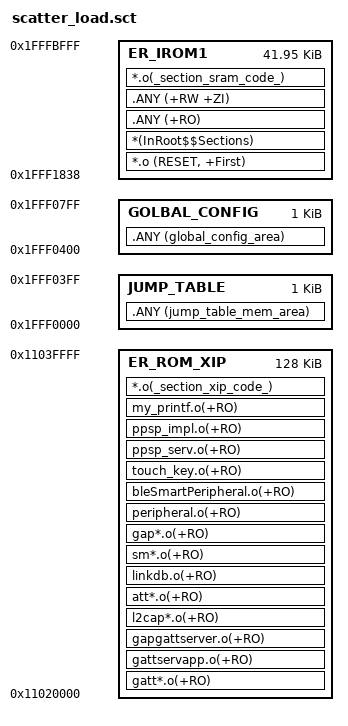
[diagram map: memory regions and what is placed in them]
; *************************************************************
; *** Scatter-Loading Description File generated by uVision ***
; *************************************************************


LR_IROM1 0x1fff1838 0x0A7C8 {  ; load region size_region
  ER_IROM1 0x1fff1838 0x0A7C8  {  ; load address = execution address
   *.o (RESET, +First)
   *(InRoot$$Sections)  
   .ANY (+RO) 
   .ANY (+RW +ZI)
   *.o(_section_sram_code_)
  }
}

 ;LR_IROM3 0x20000000 0x00010000 {  ; load region size_region 
  ;RF_DTM_RO 0x20000000 0x0003000  {  ; load address = execution address
    ;;*.o (RESET, +First)
    ;;*(InRoot$$Sections)
    ;rf_phy_driver.o (i.rf_phy_dtm_zigbee_pkt_gen)
    ;rf_phy_driver.o (i.rf_phy_direct_test) 
    ;rf_phy_driver.o (i.rf_phy_dtm_cmd_parse) 
    ;rf_phy_driver.o (i.rf_phy_dtm_evt_send) 
    ;rf_phy_driver.o (i.rf_phy_dtm_trigged) 
   ;}
;}
 
LR_IROM2  0x1fff0000 0x00800 {
  JUMP_TABLE 0x1fff0000 0x00400  {
   .ANY (jump_table_mem_area) 
	
  }
  GOLBAL_CONFIG 0x1fff0400 0x00400  {
   .ANY (global_config_area) 
	
  }  
 } 


LR_ROM_XIP  0x11020000 0x020000 {
  ER_ROM_XIP 0x11020000 0x020000  {  ; load address = execution address
   ;devinfoservice.o(+RO)
   gatt*.o(+RO)
   gattservapp.o(+RO)
   gapgattserver.o(+RO)
   l2cap*.o(+RO)
   att*.o(+RO)
   linkdb.o(+RO)
   sm*.o(+RO)
   gap*.o(+RO)
   ;gapbondmgr.o(+RO)
   peripheral.o(+RO)
   bleSmartPeripheral.o(+RO)
   ;simpleGATTprofile.o(+RO)
   touch_key.o(+RO)
   ;pwm.o(+RO)
   ppsp_serv.o(+RO)
   ppsp_impl.o(+RO)
   my_printf.o(+RO)
   ;osal_snv.o(+RO)
   *.o(_section_xip_code_)
  }
 }  


